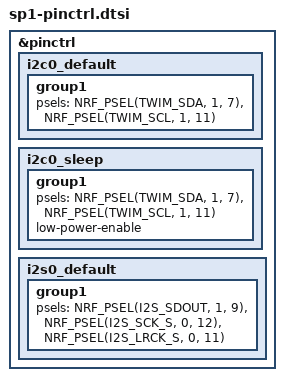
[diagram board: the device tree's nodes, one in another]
&pinctrl {
	i2c0_default: i2c0_default {
		group1 {
			psels = <NRF_PSEL(TWIM_SDA, 1, 7)>,
				<NRF_PSEL(TWIM_SCL, 1, 11)>;
		};
	};
	i2c0_sleep: i2c0_sleep {
		group1 {
			psels = <NRF_PSEL(TWIM_SDA, 1, 7)>,
				<NRF_PSEL(TWIM_SCL, 1, 11)>;
			low-power-enable;
		};
	};
	i2s0_default: i2s0_default {
		group1 {
			psels = <NRF_PSEL(I2S_SDOUT, 1, 9)>,
				<NRF_PSEL(I2S_SCK_S, 0, 12)>,
				<NRF_PSEL(I2S_LRCK_S, 0, 11)>;
		};
	};
};
